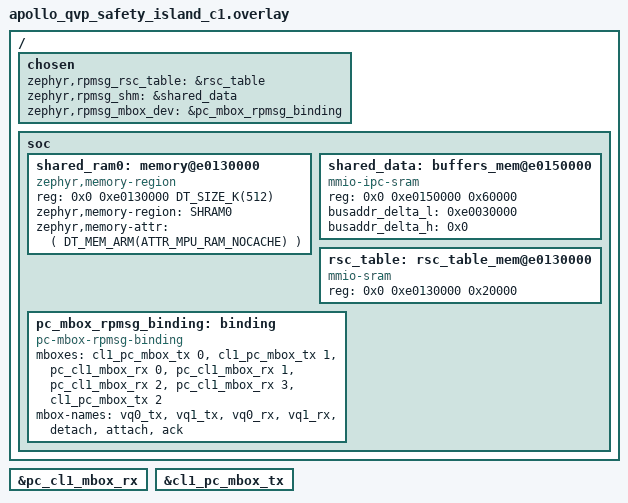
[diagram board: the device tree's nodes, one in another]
/*
 * SPDX-FileCopyrightText: <text>Copyright 2026 Arm Limited and/or its
 * affiliates <open-source-office@arm.com></text>
 *
 * SPDX-License-Identifier: Apache-2.0
 */

/ {
	chosen {
		zephyr,rpmsg_rsc_table = &rsc_table;
		zephyr,rpmsg_shm = &shared_data;
		zephyr,rpmsg_mbox_dev = &pc_mbox_rpmsg_binding;
	};

	soc {
		shared_ram0: memory@e0130000 {
			compatible = "zephyr,memory-region", "mmio-sram";
			reg = <0x0 0xe0130000 DT_SIZE_K(512)>;
			zephyr,memory-region = "SHRAM0";
			zephyr,memory-attr = <( DT_MEM_ARM(ATTR_MPU_RAM_NOCACHE) )>;
		};

		shared_data: buffers_mem@e0150000 {
			compatible = "mmio-ipc-sram";
			reg = <0x0 0xe0150000 0x60000>;
			busaddr_delta_l = <0xe0030000>;
			busaddr_delta_h = <0x0>;
		};

		rsc_table: rsc_table_mem@e0130000 {
			compatible = "mmio-sram";
			reg = <0x0 0xe0130000 0x20000>;
		};

		pc_mbox_rpmsg_binding: binding {
			compatible = "pc-mbox-rpmsg-binding";
			mboxes = <&cl1_pc_mbox_tx 0>, <&cl1_pc_mbox_tx 1>,
				 <&pc_cl1_mbox_rx 0>, <&pc_cl1_mbox_rx 1>,
				 <&pc_cl1_mbox_rx 2>, <&pc_cl1_mbox_rx 3>,
				 <&cl1_pc_mbox_tx 2>;

			mbox-names = "vq0_tx", "vq1_tx", "vq0_rx",
				     "vq1_rx", "detach", "attach",
				     "ack";
		};
	};
};

&pc_cl1_mbox_rx {
	status = "okay";
};

&cl1_pc_mbox_tx {
	status = "okay";
};
